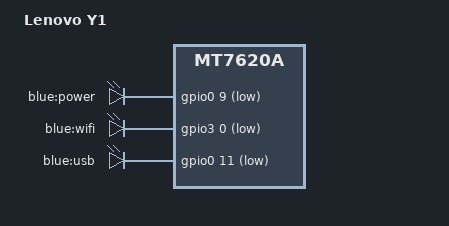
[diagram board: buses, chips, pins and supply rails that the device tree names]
#include "mt7620a_lenovo_newifi-y1.dtsi"

/ {
	compatible = "lenovo,newifi-y1", "ralink,mt7620a-soc";
	model = "Lenovo Y1";

	aliases {
		led-boot = &led_power;
		led-failsafe = &led_power;
		led-running = &led_power;
		led-upgrade = &led_power;
	};

	leds {
		compatible = "gpio-leds";

		led_power: power {
			label = "blue:power";
			gpios = <&gpio0 9 GPIO_ACTIVE_LOW>;
		};

		wlan0 {
			label = "blue:wifi";
			gpios = <&gpio3 0 GPIO_ACTIVE_LOW>;
		};

		usb {
			label = "blue:usb";
			gpios = <&gpio0 11 GPIO_ACTIVE_LOW>;
			trigger-sources = <&ohci_port1>, <&ehci_port1>;
			linux,default-trigger = "usbport";
		};

	};
};

&ethernet {
	pinctrl-names = "default";
	pinctrl-0 = <&ephy_pins>;
	
	mtd-mac-address = <&factory 0x4>;
	mediatek,portmap = "wllll";
};
